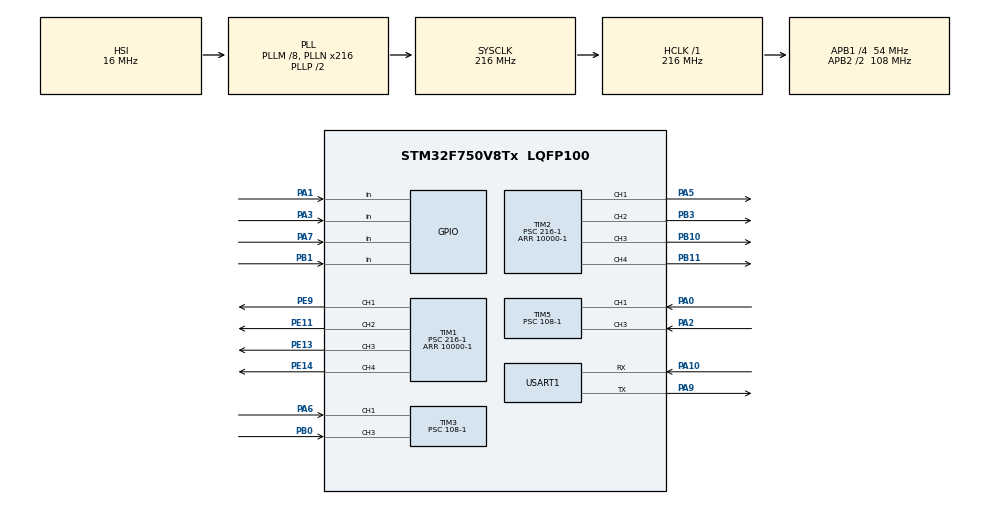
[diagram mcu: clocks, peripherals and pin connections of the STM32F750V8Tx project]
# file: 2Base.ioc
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Mcu.Family=STM32F7
Mcu.Name=STM32F750V8Tx
Mcu.Package=LQFP100
NVIC.PriorityGroup=NVIC_PRIORITYGROUP_4
NVIC.TIM3_IRQn=true\:1\:0\:true\:false\:true\:true\:true\:true
NVIC.TIM5_IRQn=true\:1\:0\:true\:false\:true\:true\:true\:true
NVIC.TIM6_DAC_IRQn=true\:0\:0\:false\:false\:true\:true\:true\:true
NVIC.USART1_IRQn=true\:0\:0\:true\:false\:true\:true\:true\:true
PA0/WKUP.Signal=S_TIM5_CH1
PA1.Signal=GPIO_Input
PA10.Mode=Asynchronous
PA10.Signal=USART1_RX
PA2.Signal=S_TIM5_CH3
PA3.Signal=GPIO_Input
PA5.Signal=S_TIM2_CH1_ETR
PA6.Signal=S_TIM3_CH1
PA7.Signal=GPIO_Input
PA9.Mode=Asynchronous
PA9.Signal=USART1_TX
PB0.Signal=S_TIM3_CH3
PB1.Signal=GPIO_Input
PB10.Signal=S_TIM2_CH3
PB11.Signal=S_TIM2_CH4
PB3.Signal=S_TIM2_CH2
PE11.Signal=S_TIM1_CH2
PE13.Signal=S_TIM1_CH3
PE14.Signal=S_TIM1_CH4
PE9.Signal=S_TIM1_CH1
PH0/OSC_IN.Mode=HSE-External-Oscillator
PH0/OSC_IN.Signal=RCC_OSC_IN
PH1/OSC_OUT.Mode=HSE-External-Oscillator
PH1/OSC_OUT.Signal=RCC_OSC_OUT
ProjectManager.HeapSize=0x200
ProjectManager.StackSize=0x400
ProjectManager.TargetToolchain=MDK-ARM V5.32
RCC.AHBFreq_Value=216000000
RCC.APB1CLKDivider=RCC_HCLK_DIV4
RCC.APB1Freq_Value=54000000
RCC.APB1TimFreq_Value=108000000
RCC.APB2CLKDivider=RCC_HCLK_DIV2
RCC.APB2Freq_Value=108000000
RCC.APB2TimFreq_Value=216000000
RCC.CortexFreq_Value=216000000
RCC.HCLKFreq_Value=216000000
RCC.HSE_VALUE=25000000
RCC.HSI_VALUE=16000000
RCC.LSE_VALUE=32768
RCC.PLLM=8
RCC.PLLN=216
RCC.SYSCLKFreq_VALUE=216000000
RCC.SYSCLKSource=RCC_SYSCLKSOURCE_PLLCLK
RCC.USBFreq_Value=216000000
RCC.VCOOutputFreq_Value=432000000
SH.S_TIM1_CH1.0=TIM1_CH1,PWM Generation1 CH1
SH.S_TIM1_CH2.0=TIM1_CH2,PWM Generation2 CH2
SH.S_TIM1_CH3.0=TIM1_CH3,PWM Generation3 CH3
SH.S_TIM1_CH4.0=TIM1_CH4,PWM Generation4 CH4
SH.S_TIM2_CH1_ETR.0=TIM2_CH1,PWM Generation1 CH1
SH.S_TIM2_CH2.0=TIM2_CH2,PWM Generation2 CH2
SH.S_TIM2_CH3.0=TIM2_CH3,PWM Generation3 CH3
SH.S_TIM2_CH4.0=TIM2_CH4,PWM Generation4 CH4
SH.S_TIM3_CH1.0=TIM3_CH1,Input_Capture1_from_TI1
SH.S_TIM3_CH3.0=TIM3_CH3,Input_Capture3_from_TI3
SH.S_TIM5_CH1.0=TIM5_CH1,Input_Capture1_from_TI1
SH.S_TIM5_CH3.0=TIM5_CH3,Input_Capture3_from_TI3
TIM1.Channel-PWM\ Generation1\ CH1=TIM_CHANNEL_1
TIM1.Channel-PWM\ Generation2\ CH2=TIM_CHANNEL_2
TIM1.Channel-PWM\ Generation3\ CH3=TIM_CHANNEL_3
TIM1.Channel-PWM\ Generation4\ CH4=TIM_CHANNEL_4
TIM1.Period=10000-1
TIM1.Prescaler=216-1
TIM2.Channel-PWM\ Generation1\ CH1=TIM_CHANNEL_1
TIM2.Channel-PWM\ Generation2\ CH2=TIM_CHANNEL_2
TIM2.Channel-PWM\ Generation3\ CH3=TIM_CHANNEL_3
TIM2.Channel-PWM\ Generation4\ CH4=TIM_CHANNEL_4
TIM2.Period=10000-1
TIM2.Prescaler=216-1
TIM3.AutoReloadPreload=TIM_AUTORELOAD_PRELOAD_ENABLE
TIM3.Channel-Input_Capture1_from_TI1=TIM_CHANNEL_1
TIM3.Channel-Input_Capture3_from_TI3=TIM_CHANNEL_3
TIM3.Prescaler=108-1
TIM5.AutoReloadPreload=TIM_AUTORELOAD_PRELOAD_ENABLE
TIM5.Channel-Input_Capture1_from_TI1=TIM_CHANNEL_1
TIM5.Channel-Input_Capture3_from_TI3=TIM_CHANNEL_3
TIM5.Period=65535
TIM5.Prescaler=108-1
TIM6.AutoReloadPreload=TIM_AUTORELOAD_PRELOAD_ENABLE
TIM6.Period=10000
TIM6.Prescaler=108-1
USART1.VirtualMode-Asynchronous=VM_ASYNC
VP_TIM6_VS_ClockSourceINT.Mode=Enable_Timer
board=custom

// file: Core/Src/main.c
/* USER CODE BEGIN Header */
/**
  ******************************************************************************
  * @file           : main.c
  * @brief          : Main program body
  ******************************************************************************
  * @attention
  *
  * Copyright (c) 2023 STMicroelectronics.
  * All rights reserved.
  *
  * This software is licensed under terms that can be found in the LICENSE file
  * in the root directory of this software component.
  * If no LICENSE file comes with this software, it is provided AS-IS.
  *
  ******************************************************************************
  */
/* USER CODE END Header */
#include "main.h"
#include "tim.h"
#include "usart.h"
#include "gpio.h"

/* USER CODE BEGIN Includes */
#include "Motor_Power.h"
#include "Motor_PID.h"
#include "GlobalClock.h"
#include "Serial.h"
#include "usmart.h"
/* USER CODE END Includes */

void SystemClock_Config(void);

int main(void)
{

  /* MCU Configuration--------------------------------------------------------*/

  /* Reset of all peripherals, Initializes the Flash interface and the Systick. */
  HAL_Init();

  /* Configure the system clock */
  SystemClock_Config();

  /* Initialize all configured peripherals */
  MX_GPIO_Init();
  MX_TIM1_Init();
  MX_TIM2_Init();
  MX_TIM3_Init();
  MX_TIM5_Init();
  MX_TIM6_Init();
  MX_USART1_UART_Init();
  /* USER CODE BEGIN 2 */
  Serial_Init();
  usmart_dev.init(108);
//huart6(ic),7(qrcode),3(mv)

  Motor_PID_Init();
  Motor_Init();
  GlobalClock_Init();

// huart3(jy61p)
//
	Set_Chassis_Speed(0,50,0);
	delay_ms(5000);
	Set_Chassis_Speed(0,0,0);
	delay_ms(500);
  /* USER CODE END 2 */

  /* Infinite loop */
  while (1)
  {

  }
}

void SystemClock_Config(void)
{
  RCC_OscInitTypeDef RCC_OscInitStruct = {0};
  RCC_ClkInitTypeDef RCC_ClkInitStruct = {0};

  /** Configure the main internal regulator output voltage
  */
  __HAL_RCC_PWR_CLK_ENABLE();
  __HAL_PWR_VOLTAGESCALING_CONFIG(PWR_REGULATOR_VOLTAGE_SCALE1);

  /** Initializes the RCC Oscillators according to the specified parameters
  * in the RCC_OscInitTypeDef structure.
  */
  RCC_OscInitStruct.OscillatorType = RCC_OSCILLATORTYPE_HSI;
  RCC_OscInitStruct.HSIState = RCC_HSI_ON;
  RCC_OscInitStruct.HSICalibrationValue = RCC_HSICALIBRATION_DEFAULT;
  RCC_OscInitStruct.PLL.PLLState = RCC_PLL_ON;
  RCC_OscInitStruct.PLL.PLLSource = RCC_PLLSOURCE_HSI;
  RCC_OscInitStruct.PLL.PLLM = 8;
  RCC_OscInitStruct.PLL.PLLN = 216;
  RCC_OscInitStruct.PLL.PLLP = RCC_PLLP_DIV2;
  RCC_OscInitStruct.PLL.PLLQ = 2;
  if (HAL_RCC_OscConfig(&RCC_OscInitStruct) != HAL_OK)
  {
    Error_Handler();
  }

  /** Activate the Over-Drive mode
  */
  if (HAL_PWREx_EnableOverDrive() != HAL_OK)
  {
    Error_Handler();
  }

  /** Initializes the CPU, AHB and APB buses clocks
  */
  RCC_ClkInitStruct.ClockType = RCC_CLOCKTYPE_HCLK|RCC_CLOCKTYPE_SYSCLK
                              |RCC_CLOCKTYPE_PCLK1|RCC_CLOCKTYPE_PCLK2;
  RCC_ClkInitStruct.SYSCLKSource = RCC_SYSCLKSOURCE_PLLCLK;
  RCC_ClkInitStruct.AHBCLKDivider = RCC_SYSCLK_DIV1;
  RCC_ClkInitStruct.APB1CLKDivider = RCC_HCLK_DIV4;
  RCC_ClkInitStruct.APB2CLKDivider = RCC_HCLK_DIV2;

  if (HAL_RCC_ClockConfig(&RCC_ClkInitStruct, FLASH_LATENCY_7) != HAL_OK)
  {
    Error_Handler();
  }
}

void Error_Handler(void)
{
  __disable_irq();
  while (1)
  {
  }
}
